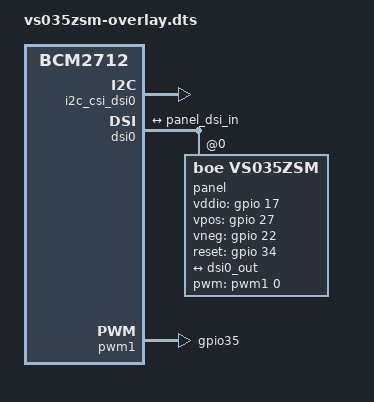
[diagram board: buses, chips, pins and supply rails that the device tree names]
/dts-v1/;
/plugin/;

/*
 * VS035ZSM Panel Overlay for Raspberry Pi 5
 *
 * Based on vc4-kms-dsi-generic structure
 * Uses DSI0 with 4 lanes, tps65132 regulator on I2C10
 * Adds PWM backlight on RP1 GPIO 35 (PWM1 Channel 3)
 */

/ {
	compatible = "brcm,bcm2712";

	/* Fragment 0: Enable tps65132 on I2C10 */
	fragment@0 {
		target = <&i2c_csi_dsi0>;
		__overlay__ {
			status = "okay";
			#address-cells = <1>;
			#size-cells = <0>;
		};
	};

	/* Fragment 1: Enable DSI0 and add panel */
	fragment@1 {
		target = <&dsi0>;
		__overlay__ {
			status = "okay";
			#address-cells = <1>;
			#size-cells = <0>;

			port {
				dsi0_out: endpoint {
					remote-endpoint = <&panel_dsi_in>;
					data-lanes = <0 1 2 3>;
					lane-polarities = <0 0 0 1 1>;
				};
			};

			panel: panel@0 {
				compatible = "boe,vs035zsm";
				reg = <0>;
				status = "okay";


				/* Power GPIOs (active high enable) */
				vddio-gpios = <&gpio 17 0>;   /* 1.8V VDDIO */
				vpos-gpios  = <&gpio 27 0>;   /* TPS65132 VPOS enable */
				vneg-gpios  = <&gpio 22 0>;   /* TPS65132 VNEG enable */
				
				/* Reset GPIO - GPIO34 on RP1 */
				reset-gpios = <&gpio 34 0>;  /* 0 = GPIO_ACTIVE_HIGH */

				/* PWM Backlight on PWM1 Channel 0 (RP1 GPIO 35) */
				/* Period: 20000ns (50kHz) */
				pwms = <&pwm1 0 20000 0>;
				
				port {
					panel_dsi_in: endpoint {
						data-lanes = <1 2 3 4>;
						remote-endpoint = <&dsi0_out>;
					};
				};

				/* Panel timing for VS035ZSM */
				// panel-timing {
				// 	clock-frequency = <42324000>;
				// 	hactive = <1440>;
				// 	vactive = <1600>;
				// 	hback-porch = <80>;
				// 	hfront-porch = <80>;
				// 	hsync-len = <40>;
				// 	vback-porch = <40>;
				// 	vfront-porch = <40>;
				// 	vsync-len = <40>;
				// };
			};
		};
	};

	/* Fragment 2: Configure PWM1 */
	fragment@2 {
		target = <&pwm1>;
		__overlay__ {
			pinctrl-names = "default";
			pinctrl-0 = <&pwm_pins>;
			status = "okay";
		};
	};

	/* Fragment 3: Configure GPIO 35 as PWM1 */
	fragment@3 {
		target = <&gpio>;
		__overlay__ {
			pwm_pins: pwm_pins {
				function = "pwm1";
				pins = "gpio35";
				bias-disable; 
			};
		};
	};
};
